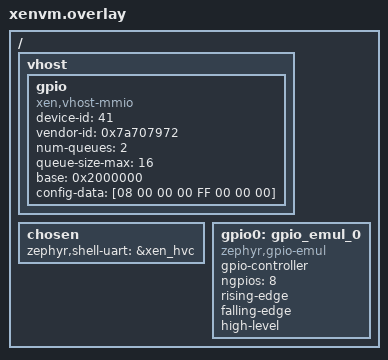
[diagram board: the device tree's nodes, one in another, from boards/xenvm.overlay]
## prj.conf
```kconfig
CONFIG_VHOST=y
CONFIG_LOG=y
CONFIG_HEAP_MEM_POOL_SIZE=8388608
CONFIG_LOG_MODE_IMMEDIATE=y
CONFIG_LOG_DEFAULT_LEVEL=3
CONFIG_VHOST_LOG_LEVEL_DBG=y
CONFIG_CONSOLE=y
CONFIG_SHELL=y
#CONFIG_XEN_SHELL=y
#CONFIG_XENSTORE_CLI_SHELL_CMDS=y
CONFIG_SHELL_BACKEND_SERIAL=y
CONFIG_SHELL_BACKEND_SERIAL_API_POLLING=y
CONFIG_GPIO=y
CONFIG_GPIO_GET_DIRECTION=y
CONFIG_GPIO_GET_CONFIG=y
```

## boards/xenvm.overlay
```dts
/*
 * Copyright (c) 2025 TOKITA Hiroshi
 *
 * SPDX-License-Identifier: Apache-2.0
 */

#include <zephyr/dt-bindings/gpio/gpio.h>
/ {
	vhost {
	    //rng {
			//compatible = "xen,vhost-mmio";
			//device-id = <4>;
			//vendor-id = <0x7a707972>; /* "zphy" */
			//num-queues = <2>;
			//queue-size-max= <16>;
			//base = <0x2000000>;
		//};
        gpio {
            compatible = "xen,vhost-mmio";
            device-id = <41>;
            vendor-id = <0x7a707972>; /* "zphy" */
            num-queues = <2>;
            queue-size-max= <16>;
            base = <0x2000000>;
            config-data = [08 00 00 00 FF 00 00 00];
        };
	};

	chosen {
		zephyr,shell-uart = &xen_hvc;
	};

	gpio0: gpio_emul_0 {
		compatible = "zephyr,gpio-emul";
		gpio-controller;
		status = "okay";
		#gpio-cells = <2>;
		ngpios = <8>;
		rising-edge;
		falling-edge;
		high-level;
	};
};
```

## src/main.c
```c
/*
 * Copyright (c) 2025 TOKITA Hiroshi
 *
 * SPDX-License-Identifier: Apache-2.0
 */

#include <zephyr/drivers/vhost.h>
#include <zephyr/drivers/vhost/vringh.h>
#include <zephyr/logging/log.h>
#include <zephyr/drivers/gpio.h>

/* Possible values of the status field */
#define VIRTIO_GPIO_STATUS_OK  0x0
#define VIRTIO_GPIO_STATUS_ERR 0x1

/* GPIO message types */
#define VIRTIO_GPIO_MSG_GET_LINE_NAMES 0x0001
#define VIRTIO_GPIO_MSG_GET_DIRECTION  0x0002
#define VIRTIO_GPIO_MSG_SET_DIRECTION  0x0003
#define VIRTIO_GPIO_MSG_GET_VALUE      0x0004
#define VIRTIO_GPIO_MSG_SET_VALUE      0x0005
#define VIRTIO_GPIO_MSG_SET_IRQ_TYPE   0x0006

/* GPIO Direction types */
#define VIRTIO_GPIO_DIRECTION_NONE 0x00
#define VIRTIO_GPIO_DIRECTION_OUT  0x01
#define VIRTIO_GPIO_DIRECTION_IN   0x02

/* GPIO interrupt types */
#define VIRTIO_GPIO_IRQ_TYPE_NONE         0x00
#define VIRTIO_GPIO_IRQ_TYPE_EDGE_RISING  0x01
#define VIRTIO_GPIO_IRQ_TYPE_EDGE_FALLING 0x02
#define VIRTIO_GPIO_IRQ_TYPE_EDGE_BOTH    0x03
#define VIRTIO_GPIO_IRQ_TYPE_LEVEL_HIGH   0x04
#define VIRTIO_GPIO_IRQ_TYPE_LEVEL_LOW    0x08

#define GPIO_EMUL_0_NODE DT_NODELABEL(gpio_emul_0)

LOG_MODULE_REGISTER(vhost);

#define QUEUE_READY_HANDLER_NAME(node_name) UTIL_CAT(node_name, _queue_ready)

#define QUEUE_READY_HANDLER_PROTODECL(sym)                                                         \
	void QUEUE_READY_HANDLER_NAME(sym)(const struct device *dev, uint16_t qid, void *data);

#define DECL_HANDLER(inst, x, y)                                                                   \
	QUEUE_READY_HANDLER_PROTODECL(DT_NODE_FULL_NAME_UNQUOTED(DT_INST(inst, xen_vhost_mmio)))

#define REGISTER_HANDLER(inst, x, y)                                                               \
	{                                                                                          \
		const struct device *dev = DEVICE_DT_GET(DT_INST(inst, xen_vhost_mmio));           \
		register_handler(dev, QUEUE_READY_HANDLER_NAME(DT_NODE_FULL_NAME_UNQUOTED(         \
					      DT_INST(inst, xen_vhost_mmio))));                    \

struct virtio_gpio_request {
	uint16_t type;
	uint16_t gpio;
	uint32_t value;
};

struct virtio_gpio_response {
	uint8_t status;
	uint8_t value;
};
struct vringh vrh_inst;

static void vringh_kick_handler(struct vringh *vrh)
{
	LOG_DBG("%s: queue_id=%lu", __func__, vrh->queue_id);
	uint16_t head;

	while (true) {
		int ret = vringh_getdesc(vrh, &riov, &wiov, &head);

		if (ret < 0) {
			LOG_ERR("vringh_getdesc failed: %d", ret);
			return;
		}

		if (ret == 0) {
			printk("Exit 0\n");
			return;
		}

		printk("riov.used: %d\n", riov.used);
		for (uint32_t s = 0; s < riov.used; s++) {
			struct virtio_gpio_request req;
			struct virtio_gpio_response resp = {0};
			struct device *dev = DEVICE_DT_GET(GPIO_EMUL_0_NODE);

			// printk("    riov.iov[0].iov_base: %p\n", riov.iov[s].iov_base);
			// printk("    riov.iov[0].iov_len: %u\n", riov.iov[s].iov_len);
			// Read request
			LOG_HEXDUMP_INF(riov.iov[0].iov_base, riov.iov[s].iov_len, "riov.iov[0]");
			mem_addr_t addr_base = (mem_addr_t)riov.iov[s].iov_base;
			req.type = sys_read16(addr_base + 0);
			req.gpio = sys_read16(addr_base + 2);
			req.value = sys_read32(addr_base + 4);

			// Case-by-case handling based on request type
			switch (req.type) {
			case VIRTIO_GPIO_MSG_GET_LINE_NAMES: {
				printk("VIRTIO_GPIO_MSG_GET_LINENAME is not implemented\n");
			} break;
			case VIRTIO_GPIO_MSG_GET_DIRECTION: {
				gpio_flags_t flags = 0;

				ret = gpio_pin_get_config(dev, req.gpio, &flags);
				if (ret < 0) {
					printk("failed to get direction\n");
					resp.status = VIRTIO_GPIO_STATUS_ERR;
					resp.value = 0;
					break;
				}
				flags &= (GPIO_OUTPUT | GPIO_INPUT);
				printk("Get direction: %d\n", flags);

				switch (flags) { // none, out, in
				case GPIO_DISCONNECTED: {
					resp.status = VIRTIO_GPIO_STATUS_OK;
					resp.value = VIRTIO_GPIO_DIRECTION_NONE;
				} break;
				case GPIO_OUTPUT: {
					resp.status = VIRTIO_GPIO_STATUS_OK;
					resp.value = VIRTIO_GPIO_DIRECTION_OUT;
				} break;
				case GPIO_INPUT: {
					resp.status = VIRTIO_GPIO_STATUS_OK;
					resp.value = VIRTIO_GPIO_DIRECTION_IN;
				} break;
				default: {
					resp.status = VIRTIO_GPIO_STATUS_ERR;
					resp.value = 0;
				} break;
				}
			} break;
			case VIRTIO_GPIO_MSG_SET_DIRECTION: {
				gpio_flags_t flags = 0;
				gpio_flags_t mask;

				if (req.value > VIRTIO_GPIO_DIRECTION_IN) {
					printk("Unexpeded value (req.value): %d\n", req.value);
					resp.status = VIRTIO_GPIO_STATUS_ERR;
					resp.value = 0;
					break;
				}

				ret = gpio_pin_get_config(dev, req.gpio, &flags);
				if (ret < 0) {
					printk("failed to set direction\n");
					resp.status = VIRTIO_GPIO_STATUS_ERR;
					resp.value = 0;
					break;
				}
				printk("Read pin status: %x\n", flags);

				// Lower bits of GPIO_OUTPUT and GPIO_INPUT
				mask = GPIO_OUTPUT | GPIO_INPUT;
				flags &= ~(flags & mask);

				// Upper bits of GPIO_OUTPUT or GPIO_INPUT
				switch (req.value) {
				case VIRTIO_GPIO_DIRECTION_NONE: {
					printk("Set direction none (req.value): %d\n", req.value);
					flags |= GPIO_DISCONNECTED;
				} break;
				case VIRTIO_GPIO_DIRECTION_OUT: {
					printk("Set direction out (req.value): %d\n", req.value);
					flags |= GPIO_OUTPUT;
				} break;
				case VIRTIO_GPIO_DIRECTION_IN: {
					printk("Set direction in (req.value): %d\n", req.value);
					flags |= GPIO_INPUT;
				} break;
				}

				ret = gpio_pin_configure(dev, req.gpio, flags);
				if (ret < 0) {
					resp.status = VIRTIO_GPIO_STATUS_ERR;
					resp.value = 0;
					break;
				}

				resp.status = VIRTIO_GPIO_STATUS_OK;
				resp.value = 0;
				printk("Write pin status: %x\n", flags);
			} break;
			case VIRTIO_GPIO_MSG_GET_VALUE: {
				ret = gpio_pin_get(dev, req.gpio);
				if (ret < 0) {
					printk("failed to get value\n");
					resp.status = VIRTIO_GPIO_STATUS_ERR;
					resp.value = 0;
					break;
				}

				printk("succeeded to get value\n");
				resp.status = VIRTIO_GPIO_STATUS_OK;
				resp.value = ret;
			} break;
			case VIRTIO_GPIO_MSG_SET_VALUE: {
				ret = gpio_pin_set(dev, req.gpio, req.value);
				if (ret < 0) {
					printk("failed to set value\n");
					resp.status = VIRTIO_GPIO_STATUS_ERR;
					resp.value = 0;
					break;
				}

				printk("succeeded to set value\n");
				resp.status = VIRTIO_GPIO_STATUS_OK;
				resp.value = 0;
			} break;
			case VIRTIO_GPIO_MSG_SET_IRQ_TYPE: {
				printk("VIRTIO_GPIO_MSG_SET_IRQ_TYPE is not implemented\n");
			} break;
			}
			// wirite response to memory
			addr_base = (mem_addr_t)wiov.iov[s].iov_base;
			sys_write8(resp.status, addr_base + 0);
			sys_write8(resp.value, addr_base + 1);
		}
		// osahou
		barrier_dmem_fence_full();

		uint32_t total_len = 0;
		for (uint32_t i = 0; i < wiov.used; i++) {
			total_len += wiov.iov[i].iov_len;
		}

		vringh_complete(vrh, head, total_len);
		printk("Notify of completion\n");

		if (vringh_need_notify(vrh) > 0) {
			vringh_notify(vrh);
		}

		/* Reset iovecs for next iteration */
		vringh_iov_reset(&riov);
		vringh_iov_reset(&wiov);
    }
}

DT_COMPAT_FOREACH_STATUS_OKAY_VARGS(xen_vhost_mmio, DECL_HANDLER, ())

int register_handler(const struct device *dev,
		     void (*handler)(const struct device *, uint16_t, void *))
{
	if (!device_is_ready(dev)) {
		LOG_ERR("VHost device %s not ready", dev->name);
		return -ENODEV;
	}

	LOG_INF("VHost device %s ready", dev->name);
	vhost_register_virtq_ready_cb(dev, handler, (void *)dev);

	return 0;
}

int main(void)
{
	DT_COMPAT_FOREACH_STATUS_OKAY_VARGS(xen_vhost_mmio, REGISTER_HANDLER, ())

	LOG_INF("VHost sample application started, waiting for guest connections...");
	k_sleep(K_FOREVER);

	return 0;
}
```

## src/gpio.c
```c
#include <zephyr/drivers/vhost.h>
#include <zephyr/drivers/vhost/vringh.h>
#include <zephyr/logging/log.h>
#include <zephyr/drivers/gpio.h>

/* Possible values of the status field */
#define VIRTIO_GPIO_STATUS_OK  0x0
#define VIRTIO_GPIO_STATUS_ERR 0x1

/* GPIO message types */
#define VIRTIO_GPIO_MSG_GET_LINE_NAMES 0x0001
#define VIRTIO_GPIO_MSG_GET_DIRECTION  0x0002
#define VIRTIO_GPIO_MSG_SET_DIRECTION  0x0003
#define VIRTIO_GPIO_MSG_GET_VALUE      0x0004
#define VIRTIO_GPIO_MSG_SET_VALUE      0x0005
#define VIRTIO_GPIO_MSG_SET_IRQ_TYPE   0x0006

/* GPIO Direction types */
#define VIRTIO_GPIO_DIRECTION_NONE 0x00
#define VIRTIO_GPIO_DIRECTION_OUT  0x01
#define VIRTIO_GPIO_DIRECTION_IN   0x02

/* GPIO interrupt types */
#define VIRTIO_GPIO_IRQ_TYPE_NONE         0x00
#define VIRTIO_GPIO_IRQ_TYPE_EDGE_RISING  0x01
#define VIRTIO_GPIO_IRQ_TYPE_EDGE_FALLING 0x02
#define VIRTIO_GPIO_IRQ_TYPE_EDGE_BOTH    0x03
#define VIRTIO_GPIO_IRQ_TYPE_LEVEL_HIGH   0x04
#define VIRTIO_GPIO_IRQ_TYPE_LEVEL_LOW    0x08

#define GPIO0_NODE DT_NODELABEL(gpio0)

LOG_MODULE_REGISTER(vhost_gpio);

static struct vhost_iovec riovec[16];
static struct vhost_iovec wiovec[16];

static struct vringh_iov riov = {
	.iov = riovec,
	.max_num = 16,
};

static struct vringh_iov wiov = {
	.iov = wiovec,
	.max_num = 16,
};

struct virtio_gpio_request {
	uint16_t type;
	uint16_t gpio;
	uint32_t value;
};

struct virtio_gpio_response {
	uint8_t status;
	uint8_t value;
};


static struct vringh vrh_inst;

static const uint8_t pin_names[] = {
	CONFIG_GPIO0_NAME0 "\0"
	CONFIG_GPIO0_NAME1 "\0"
	CONFIG_GPIO0_NAME2 "\0"
	CONFIG_GPIO0_NAME3 "\0"
	CONFIG_GPIO0_NAME4 "\0"
	CONFIG_GPIO0_NAME5 "\0"
	CONFIG_GPIO0_NAME6 "\0"
	CONFIG_GPIO0_NAME7 "\0"
	CONFIG_GPIO0_NAME8 "\0"
	CONFIG_GPIO0_NAME9 "\0"
	CONFIG_GPIO0_NAME10 "\0"
	CONFIG_GPIO0_NAME11 "\0"
	CONFIG_GPIO0_NAME12 "\0"
	CONFIG_GPIO0_NAME13 "\0"
	CONFIG_GPIO0_NAME14 "\0"
	CONFIG_GPIO0_NAME15 "\0"
	CONFIG_GPIO0_NAME16 "\0"
	CONFIG_GPIO0_NAME17 "\0"
	CONFIG_GPIO0_NAME18 "\0"
	CONFIG_GPIO0_NAME19 "\0"
	CONFIG_GPIO0_NAME20 "\0"
	CONFIG_GPIO0_NAME21 "\0"
	CONFIG_GPIO0_NAME22 "\0"
	CONFIG_GPIO0_NAME23 "\0"
	CONFIG_GPIO0_NAME24 "\0"
	CONFIG_GPIO0_NAME25 "\0"
	CONFIG_GPIO0_NAME26 "\0"
	CONFIG_GPIO0_NAME27 "\0"
	CONFIG_GPIO0_NAME28 "\0"
	CONFIG_GPIO0_NAME29 "\0"
	CONFIG_GPIO0_NAME30 "\0"
	CONFIG_GPIO0_NAME31 "\0"
};

static void vringh_kick_handler(struct vringh *vrh)
{
	LOG_DBG("%s: queue_id=%lu", __func__, vrh->queue_id);
	uint16_t head;

	while (true) {
		int ret = vringh_getdesc(vrh, &riov, &wiov, &head);

		if (ret < 0) {
			LOG_ERR("vringh_getdesc failed: %d", ret);
			return;
		}

		if (ret == 0) {
			printk("Exit 0\n");
			return;
		}

		printk("riov.used: %d\n", riov.used);
		for (uint32_t s = 0; s < riov.used; s++) {
			struct virtio_gpio_request req;
			struct virtio_gpio_response resp = {0};
			const struct device *const dev = DEVICE_DT_GET(GPIO0_NODE);
			gpio_flags_t flags = 0;

			// printk("    riov.iov[0].iov_base: %p\n", riov.iov[s].iov_base);
			// printk("    riov.iov[0].iov_len: %u\n", riov.iov[s].iov_len);
			// Read request
			LOG_HEXDUMP_INF(riov.iov[0].iov_base, riov.iov[s].iov_len, "riov.iov[0]");
			mem_addr_t addr_base = (mem_addr_t)riov.iov[s].iov_base;
			req.type = sys_read16(addr_base + 0);
			req.gpio = sys_read16(addr_base + 2);
			req.value = sys_read32(addr_base + 4);

			// Case-by-case handling based on request type
			switch (req.type) {
			case VIRTIO_GPIO_MSG_GET_LINE_NAMES:
				printk("GET_LINE_NAMES\n");
				break;
			case VIRTIO_GPIO_MSG_GET_DIRECTION:
				ret = gpio_pin_get_config(dev, req.gpio, &flags);
				printk("GET DIRE, gpio_pin_get_config: %d\n", ret);
				if (ret < 0) {
					LOG_ERR("gpio_pin_get_config failed: %d", ret);

					resp.value = 0;
					break;
				}
				flags &= (GPIO_OUTPUT | GPIO_INPUT);
				printk("Get direction: %d\n", flags);

				switch (flags) { // none, out, in
				case GPIO_DISCONNECTED:
					resp.status = VIRTIO_GPIO_STATUS_OK;
					resp.value = VIRTIO_GPIO_DIRECTION_NONE;
					break;
				case GPIO_OUTPUT:
					resp.status = VIRTIO_GPIO_STATUS_OK;
					resp.value = VIRTIO_GPIO_DIRECTION_OUT;
					break;
				case GPIO_INPUT:
					resp.status = VIRTIO_GPIO_STATUS_OK;
					resp.value = VIRTIO_GPIO_DIRECTION_IN;
					break;
				default:
					resp.status = VIRTIO_GPIO_STATUS_ERR;
					resp.value = 0;
					break;
				}
				break;
			case VIRTIO_GPIO_MSG_SET_DIRECTION:
				// Preceding 'if' statement handling the 'default' scenario
				if (req.value > VIRTIO_GPIO_DIRECTION_IN) {
					LOG_ERR("Unexpeded value (req.value): %d", req.value);
					resp.status = VIRTIO_GPIO_STATUS_ERR;
					resp.value = 0;
					break;
				}

				ret = gpio_pin_get_config(dev, req.gpio, &flags);
				printk("SET DIRE, gpio_pin_get_config: %d\n", ret);
				if (ret < 0) {
					LOG_ERR("gpio_pin_get_config failed: %d", ret);
					resp.status = VIRTIO_GPIO_STATUS_ERR;
					resp.value = 0;
					break;
				}
				printk("Read pin status: %x\n", flags);

				// Lower bits of GPIO_OUTPUT and GPIO_INPUT
				flags &= ~GPIO_DIR_MASK;

				// Upper bits of GPIO_OUTPUT or GPIO_INPUT
				// The default case is handled by the preceding
				// 'if' statement.
				printk("Set direction (req.value): %d\n", req.value);
				switch (req.value) {
				case VIRTIO_GPIO_DIRECTION_NONE:
					flags |= GPIO_DISCONNECTED;
					break;
				case VIRTIO_GPIO_DIRECTION_OUT:
					flags |= GPIO_OUTPUT;
					break;
				case VIRTIO_GPIO_DIRECTION_IN:
					flags |= GPIO_INPUT;
					break;
				}

				ret = gpio_pin_configure(dev, req.gpio, flags);
				if (ret < 0) {
					LOG_ERR("gpio_pin_config failed: %d", ret);
					resp.status = VIRTIO_GPIO_STATUS_ERR;
					resp.value = 0;
					break;
				}

				resp.status = VIRTIO_GPIO_STATUS_OK;
				resp.value = 0;
				printk("Write pin status: %x\n", flags);
				break;
			case VIRTIO_GPIO_MSG_GET_VALUE:
				ret = gpio_pin_get(dev, req.gpio);
				if (ret < 0) {
					LOG_ERR("gpio_pin_get failed: %d", ret);
					resp.status = VIRTIO_GPIO_STATUS_ERR;
					resp.value = 0;
					break;
				}

				printk("succeeded to get value\n");
				resp.status = VIRTIO_GPIO_STATUS_OK;
				resp.value = ret;
				break;
			case VIRTIO_GPIO_MSG_SET_VALUE:
				ret = gpio_pin_set(dev, req.gpio, req.value);
				if (ret < 0) {
					LOG_ERR("gpio_pin_set failed: %d", ret);
					resp.status = VIRTIO_GPIO_STATUS_ERR;
					resp.value = 0;
					break;
				}

				printk("succeeded to set value\n");
				resp.status = VIRTIO_GPIO_STATUS_OK;
				resp.value = 0;
				break;
			case VIRTIO_GPIO_MSG_SET_IRQ_TYPE:
				LOG_ERR("VIRTIO_GPIO_MSG_SET_IRQ_TYPE is not implemented\n");
				resp.status = VIRTIO_GPIO_STATUS_ERR;
				resp.value = 0;
				break;
			}
			// wirite response to memory
			addr_base = (mem_addr_t)wiov.iov[s].iov_base;
			if (req.type == VIRTIO_GPIO_MSG_GET_LINE_NAMES) {
				sys_write8(VIRTIO_GPIO_STATUS_OK, addr_base + 0);
				for(int i = 0; i < ARRAY_SIZE(pin_names); i++) {
					sys_write8(pin_names[i], addr_base + 1 + i);
				}
				LOG_HEXDUMP_INF(addr_base, 255 + 1, "resp_N"); // addr len string
			} else {
				sys_write8(resp.status, addr_base + 0);
				sys_write8(resp.value, addr_base + 1);
			}
		}
		// osahou
		barrier_dmem_fence_full();

		uint32_t total_len = 0;
		for (uint32_t i = 0; i < wiov.used; i++) {
			total_len += wiov.iov[i].iov_len;
		}

		vringh_complete(vrh, head, total_len);
		printk("Notify of completion %d\n", total_len);

		if (vringh_need_notify(vrh) > 0) {
			vringh_notify(vrh);
		}

		/* Reset iovecs for next iteration */
		vringh_iov_reset(&riov);
		vringh_iov_reset(&wiov);
	}
}

void gpio_queue_ready(const struct device *dev, uint16_t qid, void *data)
{
	LOG_DBG("%s(dev=%p, qid=%u, data=%p)", __func__, dev, qid, data);

	/* Initialize iovecs before descriptor processing */
	vringh_iov_init(&riov, riov.iov, riov.max_num);
	vringh_iov_init(&wiov, wiov.iov, wiov.max_num);

	int err = vringh_init_device(&vrh_inst, dev, qid, vringh_kick_handler);

	if (err) {
		LOG_ERR("vringh_init_device failed: %d", err);
		return;
	}
}
```

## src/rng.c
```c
/*
 * Copyright (c) 2025 TOKITA Hiroshi
 *
 * SPDX-License-Identifier: Apache-2.0
 */

#include <zephyr/drivers/vhost.h>
#include <zephyr/drivers/vhost/vringh.h>
#include <zephyr/logging/log.h>

LOG_MODULE_REGISTER(vhost_rng);

struct vhost_iovec riovec[16];
struct vhost_iovec wiovec[16];

struct vringh_iov riov = {
	.iov = riovec,
	.max_num = 16,
};

struct vringh_iov wiov = {
	.iov = wiovec,
	.max_num = 16,
};

struct vringh vrh_inst;

static void vringh_kick_handler(struct vringh *vrh)
{
	LOG_DBG("%s: queue_id=%lu", __func__, vrh->queue_id);
	uint16_t head;

	while (true) {
		int ret = vringh_getdesc(vrh, &riov, &wiov, &head);

		if (ret < 0) {
			LOG_ERR("vringh_getdesc failed: %d", ret);
			return;
		}

		if (ret == 0) {
			return;
		}

		/* Process writable iovecs */
		for (uint32_t s = 0; s < wiov.used; s++) {
			uint8_t *dst = wiov.iov[s].iov_base;
			uint32_t len = wiov.iov[s].iov_len;

			LOG_DBG("%s: addr=%p len=%u", __func__, dst, len);

			for (uint32_t i = 0; i < len; i++) {
				sys_write8(i, (mem_addr_t)&dst[i]);
			}
		}

		barrier_dmem_fence_full();

		uint32_t total_len = 0;

		for (uint32_t i = 0; i < wiov.used; i++) {
			total_len += wiov.iov[i].iov_len;
		}

		vringh_complete(vrh, head, total_len);

		if (vringh_need_notify(vrh) > 0) {
			vringh_notify(vrh);
		}

		/* Reset iovecs for next iteration */
		vringh_iov_reset(&riov);
		vringh_iov_reset(&wiov);
	}
}

void rng_queue_ready(const struct device *dev, uint16_t qid, void *data)
{
	LOG_DBG("%s(dev=%p, qid=%u, data=%p)", __func__, dev, qid, data);

	/* Initialize iovecs before descriptor processing */
	vringh_iov_init(&riov, riov.iov, riov.max_num);
	vringh_iov_init(&wiov, wiov.iov, wiov.max_num);

	int err = vringh_init_device(&vrh_inst, dev, qid, vringh_kick_handler);

	if (err) {
		LOG_ERR("vringh_init_device failed: %d", err);
		return;
	}
}
```
